# MKE18F16 register map
Vendor: Freescale Semiconductor, Inc.; Series: Kinetis_E; File version: 1.6
CPU: CM4 r0p1, little endian, no MPU, FPU, VTOR, 4 interrupt priority bits
Registers are 32-bit, read-write, reset 0x0 unless marked. A register's access mark holds for its fields unless they carry their own. Offsets are from the block's base; [hi:lo] are bit positions; {n}, {i} and the like mark numbered series; 'fields as' and 'values as' point back to an identical list.

## SIM — System Integration Module
Base 0x40048000; register names take the prefix SIM_
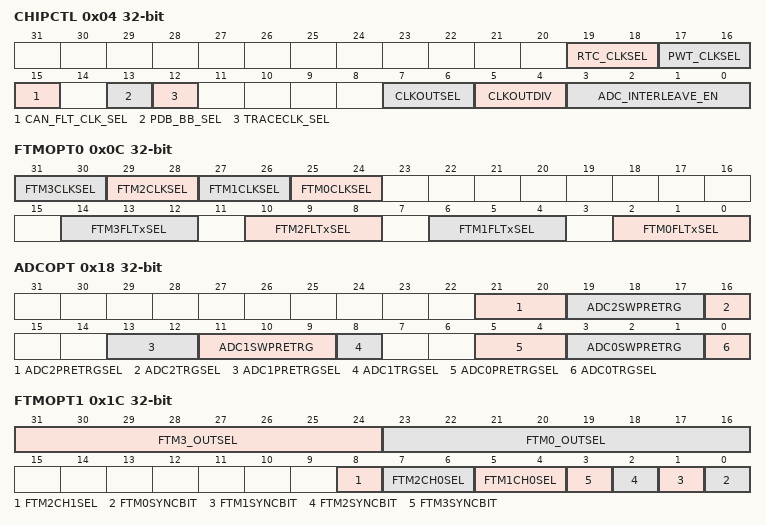
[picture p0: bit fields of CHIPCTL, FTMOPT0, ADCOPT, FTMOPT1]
0x04 CHIPCTL — Chip Control register
  [19:18] RTC_CLKSEL — RTC clock select
    0=OSC32_CLK; 1=RTC_CLKIN; 2=SOSC_CLK
  [17:16] PWT_CLKSEL — PWT clock select
    0=TCLK0; 1=TCLK1; 2=TCLK2
  [15] CAN_FLT_CLK_SEL — CAN filter clock select
    0=LPO clock; 1=SIRC clock
  [13] PDB_BB_SEL — PDB back-to-back select
    0=PDB0 channel 0 back-to-back operation with ADC0 COCO[7:0]; PDB1 channel 0 back-to-back operation with ADC1 COCO[7:0] ; PDB2 channel 0 back-to-back operation with ADC2 COCO[7:0]; 1=Channel 0 of PDB0, PDB1 and PDB2 back-to-back operation with COCO[7:0] of ADC0, ADC1 and ADC2
  [12] TRACECLK_SEL — Debug trace clock select
    0=core clock; 1=platform clock
  [7:6] CLKOUTSEL — CLKOUT Select
    1=SCGCLKOUT(SIRC/FIRC/SOSC/LPFLL); 2=RTC oscillator (OSC32) clock (32 kHz)
  [5:4] CLKOUTDIV — CLKOUT divider
    0=no divider; 1=div 2; 2=div 4
  [3:0] ADC_INTERLEAVE_EN — ADC interleave channel enable
    0=No interleave channel
0x0C FTMOPT0 — FTM Option Register 0
  [2n+25:2n+24] FTM{n}CLKSEL (n=0..3) — FTM{n} External Clock Pin Select
    0=FTM{n} external clock driven by TCLK0 pin; 1=FTM{n} external clock driven by TCLK1 pin; 2=FTM{n} external clock driven by TCLK2 pin; 3=No clock input
  [4n+2:4n] FTM{n}FLTxSEL (n=0..3) — FTM{n} Fault X Select
0x18 ADCOPT — ADC Options Register
  [21:20] ADC2PRETRGSEL — ADC2 pre-trigger source select
    0=PDB pre-trigger (default); 1=TRGMUX pre-trigger; 2=Software pre-trigger
  [19:17] ADC2SWPRETRG — ADC2 software pre-trigger sources
    0=software pre-trigger disabled; {v}=software pre-trigger {v-4} (v=4..7)
  [16] ADC2TRGSEL — ADC2 trigger source select
    0=PDB output; 1=TRGMUX output
  [13:12] ADC1PRETRGSEL — ADC1 pre-trigger source select
    values as ADC2PRETRGSEL
  [11:9] ADC1SWPRETRG — ADC1 software pre-trigger sources
    values as ADC2SWPRETRG
  [8] ADC1TRGSEL — ADC1 trigger source select
    0=PDB output; 1=TRGMUX output
  [5:4] ADC0PRETRGSEL — ADC0 pre-trigger source select
    values as ADC2PRETRGSEL
  [3:1] ADC0SWPRETRG — ADC0 software pre-trigger sources
    values as ADC2SWPRETRG
  [0] ADC0TRGSEL — ADC0 trigger source select
    0=PDB output; 1=TRGMUX output
0x1C FTMOPT1 — FTM Option Register 1
  [31:24] FTM3_OUTSEL — FTM3 channel modulation select with FTM2_CH1
    0=No modulation with FTM2_CH1; 1=Modulation with FTM2_CH1
  [23:16] FTM0_OUTSEL — FTM0 channel modulation select with FTM1_CH1
    0=No modulation with FTM1_CH1; 1=Modulation with FTM1_CH1
  [8] FTM2CH1SEL — FTM2 CH1 Select
    0=FTM2_CH1 input; 1=exclusive OR of FTM2_CH0,FTM2_CH1, and FTM1_CH1
  [7:6] FTM2CH0SEL — FTM2 CH0 Select
    0=FTM2_CH0 input; 1=CMP0 output; 2=CMP1 output; 3=CMP1 output
  [5:4] FTM1CH0SEL — FTM1 CH0 Select
    0=FTM1_CH0 input; 1=CMP0 output; 2=CMP1 output; 3=CMP2 output
  [n] FTM{n}SYNCBIT (n=0..3)
    0=No effect; 1=Write 1 to assert the TRIG1 input to FTM{n}. Software must clear this bit to allow other trigger sources to assert.
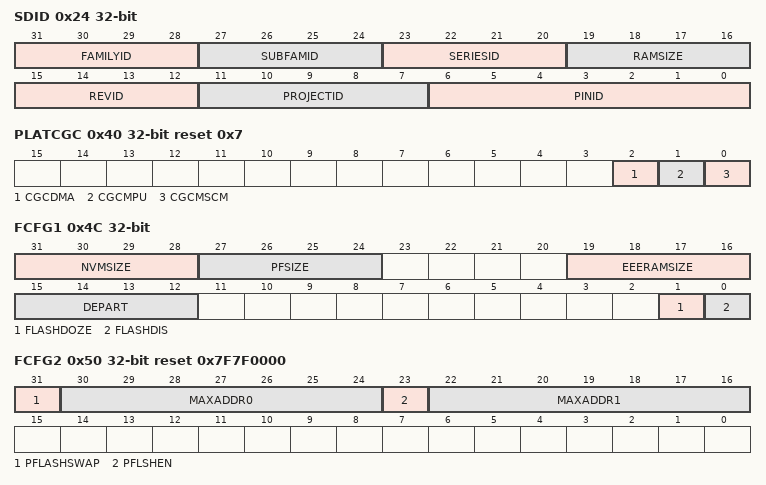
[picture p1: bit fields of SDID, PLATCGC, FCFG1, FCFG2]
0x24 SDID ro (reset mask 0xF80) — System Device Identification Register
  [31:28] FAMILYID — Kinetis E-series Family ID
    0=KE0x Family (Entry level); 1=KE1x Family (Enhanced features); 3=KE3x Family (with SLCD)
  [27:24] SUBFAMID — Kinetis E-series Sub-Family ID
    4=KEx4 Sub-family (Basic); 6=KEx6 Sub-family (with CAN); 8=KEx8 Sub-family (with dual CAN)
  [23:20] SERIESID — Kinetis Series ID
    2=Kinetis E+ series
  [19:16] RAMSIZE
    5=16 KB; 6=32 KB; 7=64 KB
  [15:12] REVID — Device revision number
  [11:7] PROJECTID
  [6:0] PINID — Pin identification
    7=64-pin; 8=80-pin; 10=100-pin
0x40 PLATCGC reset 0x7 — Platform Clock Gating Control Register
  [all] fields
    0=Clock disabled; 1=Clock enabled
  [2] CGCDMA — DMA Clock Gating Control
  [1] CGCMPU — MPU Clock Gating Control
  [0] CGCMSCM — MSCM Clock Gating Control
0x4C FCFG1 reset not defined — Flash Configuration Register 1
  [31:28] NVMSIZE ro — FlexNVM size
    0=0 KB of FlexNVM; 3=32 KB of FlexNVM; 5=64 KB of FlexNVM; 7=128 KB of FlexNVM; 9=256 KB of FlexNVM; 15=512 KB of FlexNVM
  [27:24] PFSIZE ro — Program flash size
    0=8 KB of program flash memory, 0.25 KB protection region; 1=16 KB of program flash memory, 0.5 KB protection region; 3=32 KB of program flash memory, 1 KB protection region; 5=64 KB of program flash memory, 2 KB protection region; 7=128 KB of program flash memory, 4 KB protection region; 9=256 KB of program flash memory, 8 KB protection region; 15=512 KB of program flash memory, 16 KB protection region
  [19:16] EEERAMSIZE ro — EEE SRAM SIZE
    2=4 KB; 3=2 KB; 4=1 KB; 5=512 Bytes; 6=256 Bytes; 7=128 Bytes; 8=64 Bytes; 9=32 Bytes; 15=0 Bytes
  [15:12] DEPART ro — FlexNVM partition
  [1] FLASHDOZE
    0=Flash remains enabled during Wait mode; 1=Flash is disabled for the duration of Wait mode
  [0] FLASHDIS — Flash Disable
    0=Flash is enabled; 1=Flash is disabled
0x50 FCFG2 ro reset 0x7F7F0000 — Flash Configuration Register 2
  [31] PFLASHSWAP — Program Flash Swap bit
    0=Swap is not active; 1=Swap is active
  [30:24] MAXADDR0 — Max address block 0
  [23] PFLSHEN — Program Flash Enable bit
    0=Disables the program flash; 1=Enables the program flash
  [22:16] MAXADDR1 — Max address block 1
0x54 UIDH ro — Unique Identification Register High
  [31:0] UID127_96 — Unique Identification
0x58 UIDMH ro — Unique Identification Register Mid-High
  [31:0] UID95_64 — Unique Identification
0x5C UIDML ro — Unique Identification Register Mid Low
  [31:0] UID63_32 — Unique Identification
0x60 UIDL ro — Unique Identification Register Low
  [31:0] UID31_0 — Unique Identification
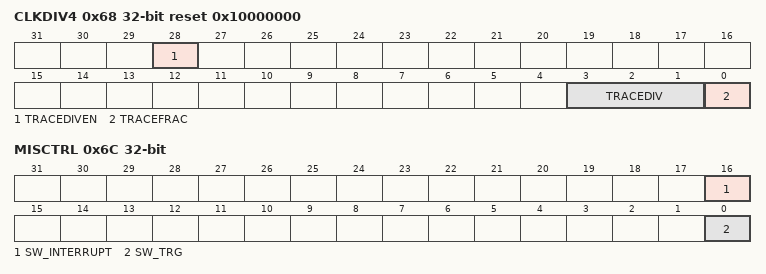
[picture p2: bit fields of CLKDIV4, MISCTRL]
0x68 CLKDIV4 reset 0x10000000 — System Clock Divider Register 4
  [28] TRACEDIVEN — Debug Trace Divider Control
    0=Debug trace divider disabled; 1=Debug trace divider enabled
  [3:1] TRACEDIV — Trace clock divider divisor To configure TRACEDIV, the user must disable TRACEDIVEN at first, and then enable it after setting TRACEDIV.
  [0] TRACEFRAC — Trace clock divider fraction To configure TRACEDIV and TRACEFRAC, the user must clear TRACEDIVEN at first to disable the trace clock divide function.
0x6C MISCTRL — Miscellaneous Control register
  [16] SW_INTERRUPT — Software Interrupt
    0=Disables software interrupt; 1=Software can send an interrupt to CPU
  [0] SW_TRG — Software Trigger bit to TRGMUX
